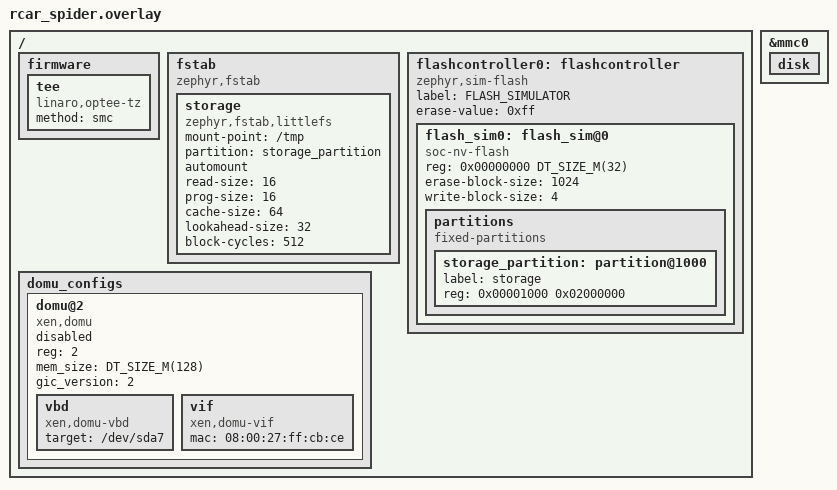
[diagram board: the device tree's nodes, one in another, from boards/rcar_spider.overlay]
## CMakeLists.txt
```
#
# Copyright (C) 2023 Renesas Electronics Corporation.
# Copyright (C) 2023 EPAM Systems, Inc.
#
# SPDX-License-Identifier: Apache-2.0
#

cmake_minimum_required(VERSION 3.20.0)

find_package(Zephyr REQUIRED HINTS $ENV{ZEPHYR_BASE})

include($ENV{ZEPHYR_BASE}/cmake/app/boilerplate.cmake NO_POLICY_SCOPE)

project(aoszephyrapp)

# ######################################################################################################################
# Config
# ######################################################################################################################

set(AOS_CORE_CONFIG aoscoreconfig.hpp)

# ######################################################################################################################
# Includes
# ######################################################################################################################

zephyr_include_directories(${CMAKE_CURRENT_BINARY_DIR} ${CMAKE_CURRENT_BINARY_DIR}/proto src)
zephyr_include_directories_ifdef(CONFIG_NATIVE_APPLICATION mocks/include)

# ######################################################################################################################
# Build in Aos Root CA
# ######################################################################################################################

if(CONFIG_AOS_ROOT_CA_PATH)
    target_sources(app PRIVATE src/rootca/rootca.S)
endif()

# ######################################################################################################################
# Generate OPTEE TA tables
# ######################################################################################################################

if(CONFIG_TA_DEPLOY_DIR)
    file(MAKE_DIRECTORY ${CMAKE_CURRENT_BINARY_DIR}/optee)

    set(GENERATED_DIRECTORY ${CMAKE_CURRENT_BINARY_DIR}/optee)

    execute_process(
        COMMAND ${PYTHON_EXECUTABLE} ${CMAKE_CURRENT_SOURCE_DIR}/scripts/gen_ta_src.py -s
                ${CMAKE_CURRENT_BINARY_DIR}/${CONFIG_TA_DEPLOY_DIR} -p -o ${GENERATED_DIRECTORY}/ta_table
    )

    include_directories(app PRIVATE ${CMAKE_CURRENT_BINARY_DIR}/${CONFIG_TA_DEPLOY_DIR})
    target_sources(app PRIVATE ${GENERATED_DIRECTORY}/ta_table.c ${GENERATED_DIRECTORY}/ta_table.S)
endif()

# ######################################################################################################################
# Definitions
# ######################################################################################################################

# Aos core configuration
add_definitions(-include ${AOS_CORE_CONFIG})

# ######################################################################################################################
# Compile options
# ######################################################################################################################

# Add stack usage warning
target_compile_options(app PRIVATE -Wstack-usage=2048)

# ######################################################################################################################
# Taget
# ######################################################################################################################

target_sources(
    app
    PRIVATE src/main.cpp
            src/app/app.cpp
            src/clocksync/clocksync.cpp
            src/communication/channelmanager.cpp
            src/communication/tlschannel.cpp
            src/communication/channel.cpp
            src/communication/channelmanager.cpp
            src/downloader/downloader.cpp
            src/iamclient/iamclient.cpp
            src/image/imagehandler.cpp
            src/logger/fsbackend.cpp
            src/logger/logger.cpp
            src/logprovider/fslogreader.cpp
            src/logprovider/logprovider.cpp
            src/monitoring/resourceusageprovider.cpp
            src/nodeinfoprovider/nodeinfoprovider.cpp
            src/ocispec/ocispec.cpp
            src/provisionmanager/provisionmanagercallback.cpp
            src/resourcemanager/resourcemanager.cpp
            src/runner/consolereader.cpp
            src/runner/runner.cpp
            src/smclient/openhandler.cpp
            src/smclient/smclient.cpp
            src/storage/storage.cpp
            src/utils/checksum.cpp
            src/utils/fsplatform.cpp
            src/utils/utils.cpp
)

# use pipe for native posix
target_sources_ifdef(CONFIG_NATIVE_APPLICATION app PRIVATE src/communication/socket.cpp)

# use xenvchan for xen
target_sources_ifndef(CONFIG_NATIVE_APPLICATION app PRIVATE src/communication/xenvchan.cpp)

# Enable vchannels and xrun mocks for native posix
target_sources_ifdef(
    CONFIG_NATIVE_APPLICATION
    app
    PRIVATE
    mocks/vch/vch.cpp
    mocks/xenlib/xenconsole.cpp
    mocks/xenlib/xendommgmt.cpp
    mocks/xrun/xrun.cpp
    mocks/xstat/xstat.cpp
)

# Include domain IPL and dtb for xen_dom0 snippet
target_sources_ifdef(CONFIG_XEN_DOM0 app PRIVATE src/domains/dom_runner.c src/domains/domain_bins.S)

# Include source files for DomD support

target_sources_ifdef(CONFIG_SOC_SERIES_RCAR_GEN4 app PRIVATE src/domains/domd/domd_cfg_spider.c)
target_sources_ifdef(CONFIG_BOARD_RCAR_SALVATOR_XS_M3 app PRIVATE src/domains/domd/domd_cfg_salvator_xs.c)
target_sources_ifdef(CONFIG_BOARD_RCAR_H3ULCB_CA57 app PRIVATE src/domains/domd/domd_cfg_h3ulcb.c)

# Include configuration source file for DomU
target_sources_ifdef(CONFIG_DOMU_ENABLE app PRIVATE src/domains/domu/domu_cfg.c)

# Include HW-specific source file
target_sources_ifndef(CONFIG_NATIVE_APPLICATION app PRIVATE src/bsp/reboot.c src/bsp/mount.c)
target_sources_ifdef(CONFIG_FILE_SYSTEM_LITTLEFS app PRIVATE src/bsp/mount_littlefs.c)
target_sources_ifdef(CONFIG_FAT_FILESYSTEM_ELM app PRIVATE src/bsp/mount_fatfs.c)

# ######################################################################################################################
# Versioning
# ######################################################################################################################

find_package(Git)

if(NOT GIT_FOUND)
    set(GIT_EXECUTABLE git)
endif()

set(CMAKE_MODULE_PATH ${PROJECT_SOURCE_DIR}/cmake)

add_custom_target(
    version
    COMMAND
        ${CMAKE_COMMAND} -D GIT_EXECUTABLE=${GIT_EXECUTABLE} -D INPUT_FILE=${CMAKE_SOURCE_DIR}/src/version.hpp.in -D
        OUTPUT_FILE=${CMAKE_CURRENT_BINARY_DIR}/version.hpp -D GIT_SOURCE_DIR=${CMAKE_SOURCE_DIR} -P
        ${CMAKE_MODULE_PATH}/GenerateVersion.cmake
)

add_dependencies(app version)

# ######################################################################################################################
#  Generate API
# ######################################################################################################################

find_package(CoreAPI)

set(CORE_API_CXX_FLAGS
    -I${CMAKE_CURRENT_SOURCE_DIR}/src
    -I${CMAKE_CURRENT_SOURCE_DIR}/../aos_core_lib_cpp/include
    -imacros
    ${AUTOCONF_H}
    -include
    ${AOS_CORE_CONFIG}
    -DARCH_STACK_PTR_ALIGN=16
)

core_api_generate(${CMAKE_CURRENT_SOURCE_DIR}/../aos_core_api ${CMAKE_CURRENT_SOURCE_DIR}/scripts)

# ######################################################################################################################
# mbedTLS
# ######################################################################################################################

# Enable AESNI for posix 32bit
if(${CONFIG_BOARD_NATIVE_POSIX})
    target_compile_options(mbedTLS INTERFACE -mpclmul -msse2 -maes)
endif()

# WA to have get time on zephyr
target_compile_definitions_ifndef(CONFIG_NATIVE_APPLICATION mbedTLS INTERFACE _POSIX_VERSION=200809L)

# Add Aos psa driver

set(mbedtls_source_dir "${APPLICATION_SOURCE_DIR}/../modules/crypto/mbedtls")
set(aoscore_source_dir "${APPLICATION_SOURCE_DIR}/../aos_core_lib_cpp")

set_source_files_properties(
    ${mbedtls_source_dir}/library/psa_crypto_driver_wrappers_no_static.c ${mbedtls_source_dir}/library/psa_crypto.c
    TARGET_DIRECTORY mbedTLS PROPERTIES HEADER_FILE_ONLY ON
)

target_include_directories(mbedTLSCrypto PRIVATE ${mbedtls_source_dir}/library)

target_sources(
    mbedTLSCrypto
    PRIVATE ${aoscore_source_dir}/src/common/crypto/mbedtls/drivers/psa_crypto_driver_wrappers_no_static.c
            ${aoscore_source_dir}/src/common/crypto/mbedtls/drivers/psa_crypto.c ${mbedtls_source_dir}/library/pk_ecc.c
)

target_sources(mbedTLSX509 PRIVATE ${mbedtls_source_dir}/library/x509write.c)

# ######################################################################################################################
# External libs
# ######################################################################################################################

include(ExternalProject)

zephyr_get_include_directories_for_lang_as_string(CXX includes)
zephyr_get_system_include_directories_for_lang_as_string(CXX system_includes)
zephyr_get_compile_definitions_for_lang_as_string(CXX definitions)
zephyr_get_compile_options_for_lang_as_string(CXX options)

set(external_project_cxx_flags "${includes} ${system_includes} -imacros ${AUTOCONF_H} ${definitions} ${options}")

# ######################################################################################################################
# aos_core_lib_cpp
# ######################################################################################################################

# add mbedTLS includes and defines for Aos core lib
set(mbedtls_includes "-I$<JOIN:$<TARGET_PROPERTY:mbedTLS,INTERFACE_INCLUDE_DIRECTORIES>, -I>")
set(mbedtls_definitions "-D$<JOIN:$<TARGET_PROPERTY:mbedTLS,INTERFACE_COMPILE_DEFINITIONS>, -D>")

set(aos_cxx_flags
    "${external_project_cxx_flags} -include ${AOS_CORE_CONFIG} ${mbedtls_includes} '${mbedtls_definitions}' \
    -Wno-pedantic -Wno-error"
)
set(aoscore_build_dir ${CMAKE_CURRENT_BINARY_DIR}/aoscore)

ExternalProject_Add(
    aoscore
    PREFIX ${aoscore_build_dir}
    CMAKE_ARGS -DCMAKE_INSTALL_PREFIX=${aoscore_build_dir}
               -DCMAKE_C_COMPILER=${CMAKE_C_COMPILER}
               -DCMAKE_CXX_COMPILER=${CMAKE_CXX_COMPILER}
               -DCMAKE_SYSTEM_NAME=${CMAKE_SYSTEM_NAME}
               -DCMAKE_SYSTEM_PROCESSOR=${CMAKE_SYSTEM_PROCESSOR}
               -DCMAKE_CXX_FLAGS=${aos_cxx_flags}
               -DWITH_MBEDTLS=OFF
    SOURCE_DIR ${aoscore_source_dir}
    BUILD_BYPRODUCTS ${aoscore_build_dir}/lib/libaossm.a ${aoscore_build_dir}/lib/libaosiam.a
                     ${aoscore_build_dir}/lib/libaoscommon.a ${aoscore_build_dir}/lib/libaoscrypto.a
    DEPENDS zephyr_interface
)

file(MAKE_DIRECTORY ${aoscore_build_dir}/include)

# aossm

add_library(aossm STATIC IMPORTED GLOBAL)

add_dependencies(aossm aoscore)

set_target_properties(aossm PROPERTIES IMPORTED_LOCATION ${aoscore_build_dir}/lib/libaossm.a)
set_target_properties(aossm PROPERTIES INTERFACE_INCLUDE_DIRECTORIES ${aoscore_build_dir}/include)

target_link_libraries(app PUBLIC aossm)

# aosiam

add_library(aosiam STATIC IMPORTED GLOBAL)

add_dependencies(aosiam aoscore)

set_target_properties(aosiam PROPERTIES IMPORTED_LOCATION ${aoscore_build_dir}/lib/libaosiam.a)
set_target_properties(aosiam PROPERTIES INTERFACE_INCLUDE_DIRECTORIES ${aoscore_build_dir}/include)

target_link_libraries(app PUBLIC aosiam)

# aoscommon

add_library(
    aoscommon STATIC ${aoscore_source_dir}/src/common/crypto/mbedtls/cryptoprovider.cpp
                     ${aoscore_source_dir}/src/common/crypto/mbedtls/driverwrapper.cpp
)

add_dependencies(aoscommon aoscore)

target_link_libraries(
    aoscommon PUBLIC ${aoscore_build_dir}/lib/libaoscommon.a ${aoscore_build_dir}/lib/libaoscrypto.a mbedTLSCrypto
)
target_include_directories(
    aoscommon
    PUBLIC ${aoscore_build_dir}/include
    PRIVATE ${CMAKE_CURRENT_SOURCE_DIR}/src
)

target_link_libraries(app PUBLIC aoscommon)

# ######################################################################################################################
# Prepare softhsm2 config
# ######################################################################################################################

if(CONFIG_NATIVE_APPLICATION)
    set(tokendir ${CONFIG_AOS_HSM_DIR})

    if(NOT IS_ABSOLUTE ${tokendir})
        set(tokendir ${CMAKE_CURRENT_BINARY_DIR}/${tokendir})
    endif()

    file(COPY misc/softhsm2.conf DESTINATION ${CMAKE_CURRENT_BINARY_DIR}/softhsm)
    file(APPEND ${CMAKE_CURRENT_BINARY_DIR}/softhsm/softhsm2.conf "directories.tokendir = ${tokendir}/\n")
endif()
```

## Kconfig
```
# Copyright (C) 2023 Renesas Electronics Corporation.
# Copyright (C) 2023 EPAM Systems, Inc.
#
# SPDX-License-Identifier: Apache-2.0

mainmenu "Aos zephyr application"

config AOS_ENABLE
	bool "Enable Aos"
	default y

config AOS_DOMD_ID
	int "DomD id"
	default 1

config AOS_CHAN_TX_PATH
	string "Path to TX channel"
	depends on !NATIVE_APPLICATION
	default "/local/domain/1/tmp/vchan/aos/tx"

config AOS_CHAN_RX_PATH
	string "Path to RX channel"
	depends on !NATIVE_APPLICATION
	default "/local/domain/1/tmp/vchan/aos/rx"

config AOS_REBOOT_XEN_STORE_PATH
	string "Path to user reboot request"
	default "/local/domain/1/data/user-reboot"

config AOS_DISK_MOUNT_POINT
	string "Disk mount point"
	default "/lfs"

config AOS_LOG_BACKEND_FS_DIR
	string "Path to the log directory"
	default "/lfs/aos/logs"

config AOS_LOG_BACKEND_FS_FILE_SIZE
	int "Log file size"
	default 16384

config AOS_LOG_BACKEND_FS_FILE_PREFIX
	string "Log file prefix"
	default "log_"

config AOS_LOG_BACKEND_FS_FILES_LIMIT
	int "Log file count"
	default 8

config AOS_STORAGE_DIR
	string "Path to the storage"
	default "/lfs/aos/storage"

config AOS_RUNTIME_DIR
	string "Aos runtime dir"
	default "/tmp/aos/runtime"

config AOS_DOWNLOAD_DIR
	string "Aos download dir"
	default "/lfs/aos/download"

config AOS_SERVICES_DIR
	string "Aos services dir"
	default "/lfs/aos/services"

config AOS_LAYERS_DIR
	string "Aos layers dir"
	default "/lfs/aos/layers"

config AOS_LAUNCHER_STATE_DIR
	string "Aos launcher state dir"
	default "/lfs/aos/launcher/states"

config AOS_LAUNCHER_STORAGE_DIR
	string "Aos launcher storage dir"
	default "/lfs/aos/launcher/storages"

config AOS_LAUNCHER_WORK_DIR
	string "Aos launcher work dir"
	default "/lfs/aos/launcher"

config AOS_NODE_CONFIG_FILE
	string "Node configuration file path"
	default "/lfs/aos/node_config.cfg"

config AOS_NODE_STATUS_FILE
	string "Path to provisioning state file."
	default "/lfs/aos/.nodestatus"

config AOS_NODE_ID_FILE
	string "Path to node id file."
	default "/lfs/aos/node-id"

config AOS_PKCS11_MODULE_PIN_FILE
	string "Path to PKCS11 module PIN file."
	default "/lfs/aos/.pkcs11pin"

config AOS_HSM_DIR
	string "Path HSM tokens dir."
	default "/lfs/tee"

config AOS_NODE_NAME
	string "Node name"
	default "zephyr"

config AOS_NODE_TYPE
	string "Node type"
	default "NODE_TYPE1"

config AOS_CLOCK_SYNC_SEND_PERIOD_SEC
	int "Send clock sync period in seconds"
	default 60

config AOS_CLOCK_SYNC_TIMEOUT_SEC
	int "Clock becomes unsynced if there is no clock sync update during this period."
	default 600

config AOS_CLOCK_SYNC_MAX_DIFF_MSEC
	int "Maximum allowed difference between source and current time."
	default 10000

config AOS_MAX_CPU_DMIPS
	int "Maximum CPU DMIPS"
	default 10000

config AOS_ROOT_CA_PATH
	string "Path to Aos Root CA certificate. Required to build in root CA into app image."
	default "prebuilt/rootca.pem"

config AOS_IAM_OPEN_PORT
	int "Aos IAM open port"
	default 1

config AOS_IAM_SECURE_PORT
	int "Aos IAM secure port"
	default 2

config AOS_SM_OPEN_PORT
	int "Aos SM open port"
	default 3

config AOS_SM_SECURE_PORT
	int "Aos SM secure port"
	default 4

config AOS_SOCKET_SERVER_ADDRESS
	string "Aos socket server address"
	depends on NATIVE_APPLICATION
	default "10.0.0.100"

config AOS_SOCKET_SERVER_PORT
	int "Aos socket server port"
	depends on NATIVE_APPLICATION
	default 30001

config AOS_PBHANDLER_THREAD_STACK_SIZE
	int "Aos PB handler stack size"
	default 32768

config AOS_LAUNCHER_THREAD_STACK_SIZE
	int "Aos launcher stack size"
	default 32768

config DOMD_ENABLE
	bool "Enable Domain-D creation"
	default y

config DOMD_UBOOT_PATH
	string "Location for Domain-D IPL binary"
	depends on DOMD_ENABLE
	default "prebuilt/ipl.bin"

config DOMD_DTB_PATH
	string "Location of Domain-D partial device-tree"
	depends on DOMD_ENABLE
	default "prebuilt/ipl.dtb"

config DOMU_ENABLE
	bool "Enable Domain-U creation"

config DOMU_BIN_PATH
	string "Location for Domain-U binary"
	depends on DOMU_ENABLE
	default "prebuilt/domu.bin"

config DOMU_DTB_PATH
	string "Location for Domain-U device-tree"
	depends on DOMU_ENABLE
	default "prebuilt/domu.dtb"

config TA_DEPLOY_DIR
	string "Location of optee TA's deploy dir"

module = AOS_CORE
module-str = Aos core
source "subsys/logging/Kconfig.template.log_config"

module = AOS_CORE_RUNTIME
module-str = Aos core runtime
source "subsys/logging/Kconfig.template.log_config"

source "Kconfig"
```

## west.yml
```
#
# Copyright (C) 2023 Renesas Electronics Corporation.
# Copyright (C) 2023 EPAM Systems, Inc.
#
# SPDX-License-Identifier: Apache-2.0
#

# West YAML manifest for Zephyr as Xen Dom0

manifest:
  self:
    path: aos_core_zephyr

  remotes:
    - name: xen-troops
      url-base: https://github.com/xen-troops

    - name: aosedge
      url-base: https://github.com/aosedge

    - name: zephyrproject-rtos
      url-base: https://github.com/zephyrproject-rtos

  projects:
    - name: zephyr
      remote: xen-troops
      revision: "zephyr/v3.6.0/xt-v3.0.0"
      west-commands: scripts/west-commands.yml

    - name: aos_core_lib_cpp
      remote: aosedge
      revision: "v1.2.2"

    - name: aos_core_api
      remote: aosedge
      revision: "v8.2.0"

    - name: zephyr-xenlib
      remote: xen-troops
      revision: "v3.1.0"

    - name: zephyr-optee-client
      remote: xen-troops
      revision: "v0.1.1"

    - name: zephyr-xrun
      remote: xen-troops
      revision: "v0.1.0"

    - name: littlefs
      remote: zephyrproject-rtos
      revision: "ed0531d59ee37f5fb2762bcf2fc8ba4efaf82656"
      path: modules/fs/littlefs
      groups:
        - fs

    - name: fatfs
      remote: zephyrproject-rtos
      revision: "427159bf95ea49b7680facffaa29ad506b42709b"
      path: modules/fs/fatfs
      groups:
        - fs

    - name: nanopb
      remote: zephyrproject-rtos
      revision: "65cbefb4695bc7af1cb733ced99618afb3586b20"
      path: modules/lib/nanopb

    - name: mbedtls
      remote: zephyrproject-rtos
      revision: "a78176c6ff0733ba08018cba4447bd3f20de7978"
      path: modules/crypto/mbedtls
      groups:
        - crypto
```

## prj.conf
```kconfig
#
# Copyright (c) 2023 EPAM Systems
#
# SPDX-License-Identifier: Apache-2.0
#

# ######################################################################################################################
# System params
# ######################################################################################################################

# Set mem parameters
CONFIG_HEAP_MEM_POOL_SIZE=2097152

# Enable userspace
CONFIG_USERSPACE=y

# Set stack size
CONFIG_MAIN_STACK_SIZE=32768
CONFIG_ISR_STACK_SIZE=8192

# Select lib
CONFIG_NEWLIB_LIBC=y
CONFIG_NEWLIB_LIBC_NANO=n

# Increase KOBJECT RODATA
CONFIG_KOBJECT_RODATA_AREA_EXTRA_BYTES=2048

# ######################################################################################################################
# Enable C++
# ######################################################################################################################

CONFIG_CPP=y
CONFIG_STD_CPP17=y

# ######################################################################################################################
# Logging, errors etc.
# ######################################################################################################################

# Enable logging

CONFIG_LOG_OUTPUT_FORMAT_CUSTOM_TIMESTAMP=y

CONFIG_LOG=y
CONFIG_LOG_CMDS=y
CONFIG_LOG_FUNC_NAME_PREFIX_ERR=n
CONFIG_LOG_FUNC_NAME_PREFIX_WRN=n
CONFIG_LOG_FUNC_NAME_PREFIX_INF=n
CONFIG_LOG_FUNC_NAME_PREFIX_DBG=n
CONFIG_LOG_DEFAULT_LEVEL=3
CONFIG_LOG_MODE_DEFERRED=y
CONFIG_LOG_BUFFER_SIZE=8192

# Set kernel default log level
CONFIG_KERNEL_LOG_LEVEL_INF=y

# Disable FS log to avoid errors duplication. We catch them by Aos errors.
CONFIG_FS_LOG_LEVEL_OFF=y

# Disable pthread cond log. It displays error on cond wait with timeout.
CONFIG_PTHREAD_COND_LOG_LEVEL_OFF=y

# Set Aos log level
CONFIG_AOS_CORE_LOG_LEVEL_DBG=y

# Set Aos runtime log level
CONFIG_AOS_CORE_RUNTIME_LOG_LEVEL_INF=y

# Enable assert for debugging purposes
# TODO: remove for release
CONFIG_ASSERT=y

# ######################################################################################################################
# POSIX configuration
# ######################################################################################################################

CONFIG_PTHREAD_IPC=y
CONFIG_POSIX_API=y
CONFIG_POSIX_FS=y
CONFIG_MAX_PTHREAD_COUNT=32
CONFIG_MAX_PTHREAD_MUTEX_COUNT=128
CONFIG_MAX_PTHREAD_COND_COUNT=32
CONFIG_MAX_THREAD_BYTES=5

# ######################################################################################################################
# 3rd parties modules
# ######################################################################################################################

# Enable mbedtls

CONFIG_MBEDTLS=y
CONFIG_MBEDTLS_BUILTIN=y
CONFIG_MBEDTLS_ENABLE_HEAP=y
CONFIG_MBEDTLS_HEAP_SIZE=262144
CONFIG_MBEDTLS_ZEPHYR_ENTROPY=y
CONFIG_MBEDTLS_USER_CONFIG_ENABLE=y
CONFIG_MBEDTLS_USER_CONFIG_FILE="aosmbedtlsconfig.h"

CONFIG_MBEDTLS_CIPHER_CCM_ENABLED=y
CONFIG_MBEDTLS_ECDH_C=y
CONFIG_MBEDTLS_ECDSA_C=y
CONFIG_MBEDTLS_ECP_C=y
CONFIG_MBEDTLS_ECP_DP_SECP256R1_ENABLED=y
CONFIG_MBEDTLS_ECP_DP_SECP384R1_ENABLED=y
CONFIG_MBEDTLS_KEY_EXCHANGE_ECDHE_ECDSA_ENABLED=y
CONFIG_MBEDTLS_KEY_EXCHANGE_RSA_ENABLED=y
CONFIG_MBEDTLS_PEM_CERTIFICATE_FORMAT=y
CONFIG_MBEDTLS_PK_WRITE_C=y
CONFIG_MBEDTLS_PSA_CRYPTO_C=y
CONFIG_MBEDTLS_SSL_MAX_CONTENT_LEN=16384
CONFIG_MBEDTLS_TLS_VERSION_1_2=y

# Enable JSON library

CONFIG_JSON_LIBRARY=y

# Enable nanopb library

CONFIG_NANOPB=y

# ######################################################################################################################
# System components
# ######################################################################################################################

# Enable shell support

CONFIG_SHELL=y
CONFIG_SHELL_BACKEND_SERIAL=y
CONFIG_SHELL_CMD_BUFF_SIZE=512
CONFIG_SHELL_STACK_SIZE=8192
CONFIG_SHELL_BACKEND_SERIAL_RX_RING_BUFFER_SIZE=512

# Enable file system

CONFIG_FILE_SYSTEM=y
CONFIG_FILE_SYSTEM_SHELL=y
CONFIG_FILE_SYSTEM_MKFS=y

# Enable cpu power management
CONFIG_PM_CPU_OPS=y

# Requires by mbedTLS for entropy. Need to be replaced with HW solution.
CONFIG_TEST_RANDOM_GENERATOR=y

# ######################################################################################################################
# Enable OP-TEE driver and client libraries
# ######################################################################################################################

CONFIG_TEE=y
CONFIG_OPTEE=y

CONFIG_OPTEE_CLIENT=y
CONFIG_OPTEE_LIBTEEC=y
CONFIG_OPTEE_LIBCKTEEC=y
CONFIG_OPTEE_TEE_SUPPLICANT=y
CONFIG_OPTEE_TEE_SUPPLICANT_AUTOINIT=n
CONFIG_OPTEE_STORAGE_ROOT="/lfs/tee"

# ######################################################################################################################
# Xen and its components
# ######################################################################################################################

# Enable xen

CONFIG_XEN_DOMAIN_MANAGEMENT=y
CONFIG_XEN_CONSOLE_SRV=y
CONFIG_XEN_STORE_SRV=y
CONFIG_XEN_LIBFDT=y
CONFIG_XEN_SHELL=y

# Enable xrun

CONFIG_XRUN=y
CONFIG_XRUN_SHELL_CMDS=y

# Enable xstat

CONFIG_XSTAT=y
CONFIG_XSTAT_SHELL_CMDS=y

# Enable vchan

CONFIG_XEN_VCH=y
CONFIG_VCH_PATH_MAXLEN=48
```

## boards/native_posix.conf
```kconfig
#
# Copyright (c) 2023 EPAM Systems
#
# SPDX-License-Identifier: Apache-2.0
#

# Enable heap auto configuration

CONFIG_SYS_HEAP_AUTO=y

# Disable Newlib

CONFIG_NEWLIB_LIBC=n
CONFIG_NEWLIB_LIBC_NANO=n

# Configure logs

CONFIG_LOG_DEFAULT_LEVEL=4
CONFIG_LOG_BACKEND_NATIVE_POSIX=y
CONFIG_SHELL_LOG_BACKEND=n
CONFIG_LOG_MODE_IMMEDIATE=y

# Enable debugging

CONFIG_NO_OPTIMIZATIONS=y
CONFIG_DEBUG_INFO=y
CONFIG_DEBUG=y

# Slow down to real time

CONFIG_NATIVE_POSIX_SLOWDOWN_TO_REAL_TIME=y

# Disable userspace

CONFIG_USERSPACE=n

# Disable errno strerror

CONFIG_MINIMAL_LIBC_STRING_ERROR_TABLE=n

# Disable posix config

CONFIG_PTHREAD_IPC=n
CONFIG_POSIX_API=n
CONFIG_POSIX_FS=n
CONFIG_MAX_PTHREAD_COUNT=0
CONFIG_MAX_PTHREAD_MUTEX_COUNT=0
CONFIG_MAX_THREAD_BYTES=0

# Disable cpu power management

CONFIG_PM_CPU_OPS=n

# Disable xen

CONFIG_XEN_DOMAIN_MANAGEMENT=n
CONFIG_XEN_CONSOLE_SRV=n
CONFIG_XEN_STORE_SRV=n
CONFIG_XEN_LIBFDT=n
CONFIG_XEN_STORE_SRV=n
CONFIG_XEN_SHELL=n

# Disable vchan

CONFIG_XEN_VCH=n

# Disable xstat

CONFIG_XSTAT=n
CONFIG_XSTAT_SHELL_CMDS=n

# Disable xrun

CONFIG_XRUN=n
CONFIG_XRUN_SHELL_CMDS=n

# Application config

CONFIG_AOS_DISK_MOUNT_POINT=".aos"
CONFIG_AOS_STORAGE_DIR=".aos/storage"
CONFIG_AOS_RUNTIME_DIR=".aos/runtime"
CONFIG_AOS_DOWNLOAD_DIR=".aos/download"
CONFIG_AOS_SERVICES_DIR=".aos/services"
CONFIG_AOS_LAUNCHER_STATE_DIR=".aos/launcher/states"
CONFIG_AOS_LAUNCHER_STORAGE_DIR=".aos/launcher/storages"
CONFIG_AOS_LAUNCHER_WORK_DIR=".aos/launcher"
CONFIG_AOS_LAYERS_DIR=".aos/layers"
CONFIG_AOS_NODE_CONFIG_FILE=".aos/node_config.cfg"
CONFIG_AOS_HSM_DIR=".aos/hsm"
CONFIG_AOS_NODE_STATUS_FILE=".aos/.nodestatus"
CONFIG_AOS_NODE_ID_FILE=".aos/node-id"
CONFIG_AOS_PKCS11_MODULE_PIN_FILE=".aos/.pkcs11pin"

# Disable OP-TEE driver and client libraries
# TEE is not supported by this platform
CONFIG_TEE=n
CONFIG_OPTEE=n

CONFIG_OPTEE_CLIENT=n
CONFIG_OPTEE_LIBTEEC=n
CONFIG_OPTEE_LIBCKTEEC=n
CONFIG_OPTEE_TEE_SUPPLICANT=n
```

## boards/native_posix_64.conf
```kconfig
#
# Copyright (c) 2023 EPAM Systems
#
# SPDX-License-Identifier: Apache-2.0
#

# Enable heap auto configuration

CONFIG_SYS_HEAP_AUTO=y

# Disable Newlib

CONFIG_NEWLIB_LIBC=n
CONFIG_NEWLIB_LIBC_NANO=n

# Configure logs

CONFIG_LOG_DEFAULT_LEVEL=4
CONFIG_LOG_BACKEND_NATIVE_POSIX=y
CONFIG_SHELL_LOG_BACKEND=n
CONFIG_LOG_MODE_IMMEDIATE=y

# Enable debugging

CONFIG_NO_OPTIMIZATIONS=y
CONFIG_DEBUG_INFO=y
CONFIG_DEBUG=y

# Slow down to real time

CONFIG_NATIVE_POSIX_SLOWDOWN_TO_REAL_TIME=y

# Disable userspace

CONFIG_USERSPACE=n

# Disable errno strerror

CONFIG_MINIMAL_LIBC_STRING_ERROR_TABLE=n

# Disable posix config

CONFIG_PTHREAD_IPC=n
CONFIG_POSIX_API=n
CONFIG_POSIX_FS=n
CONFIG_MAX_PTHREAD_COUNT=0
CONFIG_MAX_PTHREAD_MUTEX_COUNT=0
CONFIG_MAX_THREAD_BYTES=0

# Disable cpu power management

CONFIG_PM_CPU_OPS=n

# Disable xen

CONFIG_XEN_DOMAIN_MANAGEMENT=n
CONFIG_XEN_CONSOLE_SRV=n
CONFIG_XEN_STORE_SRV=n
CONFIG_XEN_LIBFDT=n
CONFIG_XEN_STORE_SRV=n
CONFIG_XEN_SHELL=n

# Disable vchan

CONFIG_XEN_VCH=n

# Disable xstat

CONFIG_XSTAT=n
CONFIG_XSTAT_SHELL_CMDS=n

# Disable xrun

CONFIG_XRUN=n
CONFIG_XRUN_SHELL_CMDS=n

# Application config

CONFIG_AOS_DISK_MOUNT_POINT=".aos"
CONFIG_AOS_STORAGE_DIR=".aos/storage"
CONFIG_AOS_RUNTIME_DIR=".aos/runtime"
CONFIG_AOS_DOWNLOAD_DIR=".aos/download"
CONFIG_AOS_SERVICES_DIR=".aos/services"
CONFIG_AOS_LAYERS_DIR=".aos/layers"
CONFIG_AOS_NODE_CONFIG_FILE=".aos/node_config.cfg"
CONFIG_AOS_HSM_DIR=".aos/hsm"
CONFIG_AOS_NODE_STATUS_FILE=".aos/.nodestatus"
CONFIG_AOS_NODE_ID_FILE=".aos/node-id"
CONFIG_AOS_PKCS11_MODULE_PIN_FILE=".aos/.pkcs11pin"

# Disable OP-TEE driver and client libraries
# TEE is not supported by this platform
CONFIG_TEE=n
CONFIG_OPTEE=n

CONFIG_OPTEE_CLIENT=n
CONFIG_OPTEE_LIBTEEC=n
CONFIG_OPTEE_LIBCKTEEC=n
CONFIG_OPTEE_TEE_SUPPLICANT=n
```

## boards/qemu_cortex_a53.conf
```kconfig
#
# Copyright (c) 2023 EPAM Systems
#
# SPDX-License-Identifier: Apache-2.0
#

# Set mem parameters

CONFIG_MAX_XLAT_TABLES=24
CONFIG_KERNEL_VM_SIZE=0x4000000
```

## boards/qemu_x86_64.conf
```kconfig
#
# Copyright (c) 2023 EPAM Systems
#
# SPDX-License-Identifier: Apache-2.0
#

CONFIG_KERNEL_VM_SIZE=0x4000000

# Enable heap auto configuration

CONFIG_SYS_HEAP_AUTO=y

# Disable littlefs

CONFIG_FILE_SYSTEM_LITTLEFS=n

# Disable cpu power management

CONFIG_PM_CPU_OPS=n

# Disable xen

CONFIG_XEN_DOMAIN_MANAGEMENT=n
CONFIG_XEN_INITIAL_DOMAIN=n
CONFIG_XEN_CONSOLE_SRV=n
CONFIG_XEN_STORE_SRV=n
CONFIG_XEN_LIBFDT=n
CONFIG_XEN_STORE_SRV=n
CONFIG_XEN_SHELL=n

# Disable xrun

CONFIG_XRUN=n
CONFIG_XRUN_SHELL_CMDS=n

# Disable vchan

CONFIG_XEN_VCH=n

# Application config

CONFIG_AOS_STORAGE_DIR=".aos/storage"
CONFIG_AOS_RUNTIME_DIR=".aos/runtime"
CONFIG_AOS_SERVICES_DIR=".aos/services"
CONFIG_AOS_UNIT_CONFIG_FILE=".aos/unit_config.cfg"
```

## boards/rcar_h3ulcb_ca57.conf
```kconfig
#
# Copyright (c) 2023 EPAM Systems
#
# SPDX-License-Identifier: Apache-2.0
#

# Kernel virtual memory size

CONFIG_KERNEL_VM_SIZE=0x4000000
CONFIG_PARTIAL_DEVICE_TREE_SIZE=90000

CONFIG_DISK_ACCESS=y
CONFIG_DISK_DRIVERS=y
CONFIG_DISK_DRIVER_MMC=y

CONFIG_RCAR_MMC_SCC_SUPPORT=n
CONFIG_SD_DATA_TIMEOUT=1000

CONFIG_XEN_DOM0=y

# Configure LittleFS

CONFIG_FILE_SYSTEM_LITTLEFS=y
CONFIG_FS_LITTLEFS_FC_HEAP_SIZE=8192
CONFIG_FS_LITTLEFS_BLK_DEV=y
CONFIG_FS_LITTLEFS_CACHE_SIZE=512
CONFIG_FS_LITTLEFS_LOOKAHEAD_SIZE=2048
CONFIG_FS_LITTLEFS_NUM_FILES=8

# Enable FLASH

CONFIG_FLASH=y
CONFIG_FLASH_SHELL=y
CONFIG_FLASH_SIMULATOR=y
CONFIG_FLASH_MAP=y
```

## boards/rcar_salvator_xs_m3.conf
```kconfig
#
# Copyright (c) 2023 EPAM Systems
#
# SPDX-License-Identifier: Apache-2.0
#

# Kernel virtual memory size

CONFIG_KERNEL_VM_SIZE=0x4000000
CONFIG_PARTIAL_DEVICE_TREE_SIZE=70000

CONFIG_DISK_ACCESS=y
CONFIG_DISK_DRIVERS=y
CONFIG_DISK_DRIVER_MMC=y

CONFIG_RCAR_MMC_SCC_SUPPORT=n
CONFIG_SD_DATA_TIMEOUT=1000

CONFIG_XEN_DOM0=y

# Configure LittleFS

CONFIG_FILE_SYSTEM_LITTLEFS=y
CONFIG_FS_LITTLEFS_FC_HEAP_SIZE=8192
CONFIG_FS_LITTLEFS_BLK_DEV=y
CONFIG_FS_LITTLEFS_CACHE_SIZE=512
CONFIG_FS_LITTLEFS_LOOKAHEAD_SIZE=2048
CONFIG_FS_LITTLEFS_NUM_FILES=8

# Enable FLASH

CONFIG_FLASH=y
CONFIG_FLASH_SHELL=y
CONFIG_FLASH_SIMULATOR=y
CONFIG_FLASH_MAP=y
```

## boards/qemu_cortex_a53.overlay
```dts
/*
 * Copyright (C) 2023 Renesas Electronics Corporation.
 * Copyright (C) 2023 EPAM Systems, Inc.
 *
 * SPDX-License-Identifier: Apache-2.0
 */

#include <mem.h>

/ {
	fstab {
		compatible = "zephyr,fstab";
		storage: storage {
			compatible = "zephyr,fstab,littlefs";
			mount-point = "/aos";
			partition = <&storage_partition>;
			automount;
			read-size = <16>;
			prog-size = <16>;
			cache-size = <64>;
			lookahead-size = <32>;
			block-cycles = <512>;
		};
	};

	flashcontroller0: flashcontroller {
		compatible = "zephyr,sim-flash";
		label = "FLASH_SIMULATOR";
		#address-cells = <1>;
		#size-cells = <1>;
		erase-value = <0xff>;
		flash_sim0: flash_sim@0 {
			compatible = "soc-nv-flash";
			reg = <0x00000000 DT_SIZE_M(16)>;
			erase-block-size = <1024>;
			write-block-size = <4>;
			partitions {
				compatible = "fixed-partitions";
				#address-cells = <1>;
				#size-cells = <1>;
			/*
			 * Storage partition will be used by FCB/LittleFS/NVS
			 * if enabled.
			 */
				storage_partition: partition@1000 {
					label = "storage";
					reg = <0x00001000 0x01000000>;
				};
			};
		};
	};
};

&sram0 {
	reg = < 0x0 0x58000000 0x0 0x2000000 >;
};
```

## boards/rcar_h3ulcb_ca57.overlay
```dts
/*
 * Copyright (C) 2023 Renesas Electronics Corporation.
 * Copyright (C) 2023 EPAM Systems, Inc.
 *
 * SPDX-License-Identifier: Apache-2.0
 */

#include <mem.h>

/delete-node/ &sd0;
/delete-node/ &gpio5;
/delete-node/ &ram;

&emmc2 {
	disk {
		status = "okay";
	};
	status = "okay";
};

/ {
	/*
	 * This node may differs on different setups, please check
	 * following line in Xen boot log to set it right:
	 * (XEN) Grant table range: 0x00000088080000-0x000000880c0000
	 * Also, add extended region 2:
	 * (XEN) [    0.928173] d0: extended region 2: 0x40000000->0x47e00000
	 *
	 * Xen passes actual values for setup in domain device tree, but Zephyr
	 * is not capable to parse and handle it in runtime.
	 */
	hypervisor: hypervisor@88080000 {
		compatible = "xen,xen";
		reg = <0x0 0x88080000 0x0 0x40000 0x0 0x40000000 0x0 0x7e00000>;
		interrupts = <GIC_PPI 0x0 IRQ_TYPE_EDGE IRQ_DEFAULT_PRIORITY>;
		interrupt-parent = <&gic>;
		status = "okay";
	};

	/*
	 * This node may differs on different setups, because Xen picks
	 * region for Domain-0 for every specific configuration. You can
	 * start Xen for your platform and check following log:
	 * (XEN) Allocating 1:1 mappings for dom0:
	 * (XEN) BANK[0] 0x00000070000000-0x00000080000000 (256MB)
	 *
	 * Xen passes actual values for setup in domain device tree, but Zephyr
	 * is not capable to parse and handle it in runtime.
	 */
	ram: memory@70000000 {
		device_type = "mmio-sram";
		reg = <0x00 0x70000000 0x00 DT_SIZE_M(256)>;
	};

	firmware {
		tee {
		compatible = "linaro,optee-tz";
		method = "smc";
		status = "okay";
		};
	};

	fstab {
		compatible = "zephyr,fstab";
		storage: storage {
			compatible = "zephyr,fstab,littlefs";
			mount-point = "/tmp";
			partition = <&storage_partition>;
			automount;
			read-size = <16>;
			prog-size = <16>;
			cache-size = <64>;
			lookahead-size = <32>;
			block-cycles = <512>;
		};
	};

	flashcontroller0: flashcontroller {
		compatible = "zephyr,sim-flash";
		label = "FLASH_SIMULATOR";
		#address-cells = <1>;
		#size-cells = <1>;
		erase-value = <0xff>;
		flash_sim0: flash_sim@0 {
			compatible = "soc-nv-flash";
			reg = <0x00000000 DT_SIZE_M(32)>;
			erase-block-size = <1024>;
			write-block-size = <4>;
			partitions {
				compatible = "fixed-partitions";
				#address-cells = <1>;
				#size-cells = <1>;
				/*
				* Storage partition will be used by FCB/LittleFS/NVS
				* if enabled.
				*/
				storage_partition: partition@1000 {
					label = "storage";
					reg = <0x00001000 0x02000000>;
				};
			};
		};
	};
};
```

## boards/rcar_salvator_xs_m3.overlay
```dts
/*
 * Copyright (C) 2023 Renesas Electronics Corporation.
 * Copyright (C) 2023 EPAM Systems, Inc.
 *
 * SPDX-License-Identifier: Apache-2.0
 */

#include <mem.h>

/delete-node/ &ram;

&emmc2 {
	disk {
		status = "okay";
	};
	status = "okay";
};

/ {
	/*
	 * This node may differs on different setups, please check
	 * following line in Xen boot log to set it right:
	 * (XEN) Grant table range: 0x00000088080000-0x000000880c0000
	 * Also, add extended region 2:
	 * (XEN) [    0.928173] d0: extended region 2: 0x40000000->0x47e00000
	 *
	 * Xen passes actual values for setup in domain device tree, but Zephyr
	 * is not capable to parse and handle it in runtime.
	 */
	hypervisor: hypervisor@88080000 {
		compatible = "xen,xen";
		reg = <0x0 0x88080000 0x0 0x40000 0x0 0x40000000 0x0 0x7e00000>;
		interrupts = <GIC_PPI 0x0 IRQ_TYPE_EDGE IRQ_DEFAULT_PRIORITY>;
		interrupt-parent = <&gic>;
		status = "okay";
	};

	/*
	 * This node may differs on different setups, because Xen picks
	 * region for Domain-0 for every specific configuration. You can
	 * start Xen for your platform and check following log:
	 * (XEN) Allocating 1:1 mappings for dom0:
	 * (XEN) BANK[0] 0x00000070000000-0x00000080000000 (256MB)
	 *
	 * Xen passes actual values for setup in domain device tree, but Zephyr
	 * is not capable to parse and handle it in runtime.
	 */
	ram: memory@70000000 {
		device_type = "mmio-sram";
		reg = <0x00 0x70000000 0x00 DT_SIZE_M(256)>;
	};

	firmware {
		tee {
		compatible = "linaro,optee-tz";
		method = "smc";
		status = "okay";
		};
	};

	fstab {
		compatible = "zephyr,fstab";
		storage: storage {
			compatible = "zephyr,fstab,littlefs";
			mount-point = "/tmp";
			partition = <&storage_partition>;
			automount;
			read-size = <16>;
			prog-size = <16>;
			cache-size = <64>;
			lookahead-size = <32>;
			block-cycles = <512>;
		};
	};

	flashcontroller0: flashcontroller {
		compatible = "zephyr,sim-flash";
		label = "FLASH_SIMULATOR";
		#address-cells = <1>;
		#size-cells = <1>;
		erase-value = <0xff>;
		flash_sim0: flash_sim@0 {
			compatible = "soc-nv-flash";
			reg = <0x00000000 DT_SIZE_M(32)>;
			erase-block-size = <1024>;
			write-block-size = <4>;
			partitions {
				compatible = "fixed-partitions";
				#address-cells = <1>;
				#size-cells = <1>;
				/*
				* Storage partition will be used by FCB/LittleFS/NVS
				* if enabled.
				*/
				storage_partition: partition@1000 {
					label = "storage";
					reg = <0x00001000 0x02000000>;
				};
			};
		};
	};
};
```

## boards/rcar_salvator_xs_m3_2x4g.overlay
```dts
#include <mem.h>

/ {
	/delete-node/memory@60000000;
	ram: memory@70000000 {
		device_type = "mmio-sram";
		reg = <0x00 0x70000000 0x00 DT_SIZE_M(256)>;
	};
  	fstab {
		compatible = "zephyr,fstab";
		storage: storage {
			compatible = "zephyr,fstab,littlefs";
			mount-point = "/aos";
			partition = <&storage_partition>;
			automount;
			read-size = <16>;
			prog-size = <16>;
			cache-size = <64>;
			lookahead-size = <32>;
			block-cycles = <512>;
		};
	};
	flashcontroller0: flashcontroller {
		compatible = "zephyr,sim-flash";
		label = "FLASH_SIMULATOR";
		#address-cells = <1>;
		#size-cells = <1>;
		erase-value = <0xff>;
		flash_sim0: flash_sim@0 {
			compatible = "soc-nv-flash";
			reg = <0x00000000 DT_SIZE_M(32)>;
			erase-block-size = <1024>;
			write-block-size = <4>;
			partitions {
				compatible = "fixed-partitions";
				#address-cells = <1>;
				#size-cells = <1>;
			/*
			 * Storage partition will be used by FCB/LittleFS/NVS
			 * if enabled.
			 */
				storage_partition: partition@1000 {
					label = "storage";
					reg = <0x00001000 0x02000000>;
				};
			};
		};
	};
};
```

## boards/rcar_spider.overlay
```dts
/*
 * Copyright (C) 2023 Renesas Electronics Corporation.
 * Copyright (C) 2023 EPAM Systems, Inc.
 *
 * SPDX-License-Identifier: Apache-2.0
 */

#include <mem.h>

&mmc0 {
	disk {
		status = "okay";
	};
	status = "okay";
};

/ {
	firmware {
		tee {
		compatible = "linaro,optee-tz";
		method = "smc";
		status = "okay";
		};
	};

	fstab {
		compatible = "zephyr,fstab";
		storage: storage {
			compatible = "zephyr,fstab,littlefs";
			mount-point = "/tmp";
			partition = <&storage_partition>;
			automount;
			read-size = <16>;
			prog-size = <16>;
			cache-size = <64>;
			lookahead-size = <32>;
			block-cycles = <512>;
		};
	};

	flashcontroller0: flashcontroller {
		compatible = "zephyr,sim-flash";
		label = "FLASH_SIMULATOR";
		#address-cells = <1>;
		#size-cells = <1>;
		erase-value = <0xff>;
		flash_sim0: flash_sim@0 {
			compatible = "soc-nv-flash";
			reg = <0x00000000 DT_SIZE_M(32)>;
			erase-block-size = <1024>;
			write-block-size = <4>;
			partitions {
				compatible = "fixed-partitions";
				#address-cells = <1>;
				#size-cells = <1>;
				/*
				* Storage partition will be used by FCB/LittleFS/NVS
				* if enabled.
				*/
				storage_partition: partition@1000 {
					label = "storage";
					reg = <0x00001000 0x02000000>;
				};
			};
		};
	};

	domu_configs {
		#address-cells = <1>;
		#size-cells = <0>;

		domu@2 {
			/*
			 * Most of the properties of this one and children nodes are default and don't appear
			 * in the resulting dts.
			 *
			 * Refer to 'xen,domu.yaml', 'xen,domu-vbd.yaml' and 'xen,domu-vif.yaml' for details.
			 */
			compatible = "xen,domu";
			reg = <2>;

			mem_size = <DT_SIZE_M(128)>;
			gic_version = <2>;

			vbd {
				compatible = "xen,domu-vbd";
				target = "/dev/sda7";
			};

			vif {
				compatible = "xen,domu-vif";
				mac = "08:00:27:ff:cb:ce";
			};

			status = "disabled";
		};
	};
};
```

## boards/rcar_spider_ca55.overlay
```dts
/*
 * Copyright (C) 2023 Renesas Electronics Corporation.
 * Copyright (C) 2023 EPAM Systems, Inc.
 *
 * SPDX-License-Identifier: Apache-2.0
 */

#include <mem.h>

/delete-node/ &ram;

&mmc0 {
	disk {
		status = "okay";
	};
	status = "okay";
};

/ {
	/*
	 * This node may differs on different setups, please check
	 * following line in Xen boot log to set it right:
	 * (XEN) Grant table range: 0x00000078080000-0x000000780c0000
	 * Also, add extended region 1:
	 * (XEN) Extended region 1: 0x40000000->0x47e00000
	 *
	 * Xen passes actual values for setup in domain device tree, but Zephyr
	 * is not capable to parse and handle it in runtime.
	 */
	hypervisor: hypervisor@78080000 {
		compatible = "xen,xen";
		reg = <0x0 0x78080000 0x0 0x40000 0x0 0x40000000 0x0 0x7e00000>;
		interrupts = <GIC_PPI 0x0 IRQ_TYPE_EDGE IRQ_DEFAULT_PRIORITY>;
		interrupt-parent = <&gic>;
		status = "okay";
	};

	/*
	 * This node may differs on different setups, because Xen picks
	 * region for Domain-0 for every specific configuration. You can
	 * start Xen for your platform and check following log:
	 * (XEN) Allocating 1:1 mappings for dom0:
	 * (XEN) BANK[0] 0x00000080000000-0x00000090000000 (256MB)
	 *
	 * Xen passes actual values for setup in domain device tree, but Zephyr
	 * is not capable to parse and handle it in runtime.
	 */
	ram: memory@80000000 {
		device_type = "mmio-sram";
		reg = <0x00 0x80000000 0x00 DT_SIZE_M(256)>;
	};

	firmware {
		tee {
		compatible = "linaro,optee-tz";
		method = "smc";
		status = "okay";
		};
	};

	fstab {
		compatible = "zephyr,fstab";
		storage: storage {
			compatible = "zephyr,fstab,littlefs";
			mount-point = "/tmp";
			partition = <&storage_partition>;
			automount;
			read-size = <16>;
			prog-size = <16>;
			cache-size = <64>;
			lookahead-size = <32>;
			block-cycles = <512>;
		};
	};

	flashcontroller0: flashcontroller {
		compatible = "zephyr,sim-flash";
		label = "FLASH_SIMULATOR";
		#address-cells = <1>;
		#size-cells = <1>;
		erase-value = <0xff>;
		flash_sim0: flash_sim@0 {
			compatible = "soc-nv-flash";
			reg = <0x00000000 DT_SIZE_M(32)>;
			erase-block-size = <1024>;
			write-block-size = <4>;
			partitions {
				compatible = "fixed-partitions";
				#address-cells = <1>;
				#size-cells = <1>;
				/*
				* Storage partition will be used by FCB/LittleFS/NVS
				* if enabled.
				*/
				storage_partition: partition@1000 {
					label = "storage";
					reg = <0x00001000 0x02000000>;
				};
			};
		};
	};
};
```

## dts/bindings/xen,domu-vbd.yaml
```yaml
# Copyright (c) 2024 EPAM Systems
# SPDX-License-Identifier: Apache-2.0

description: Xen DomU configuration for virtual block device
compatible: "xen,domu-vbd"

include: base.yaml

properties:
  backend_domain_id:
    type: int
    default: 1
    description: |
      Designates a backend domain ID for the device.
      Specifies the backend domain ID which this device should attach to.

  target:
    type: string
    required: true
    description: |
      Block device or image file path.  When this is used as a path, /dev will be prepended
      if the path doesn't start with a '/'.

      Inside xenstore it is dirrectly written to 'params':
        a free formatted string providing sufficient information for the hotplug script to attach
        the device and provide a suitable handler (ie: a block device) for blkback to use.

  script:
    type: string
    default: "/etc/xen/scripts/block"
    description: |
      Specifies that <target> is not a normal host path, but rather information to be interpreted
      by the executable program <script>, (looked for in /etc/xen/scripts, if it doesn't contain
      a slash).

      These scripts are normally called "block-<script>".

  backendtype:
    type: string
    default: "phy"
    description: |
      Specifies the backend implementation to use. Supported values: phy, tap, qdisk.

      This does not affect the guest's view of the device.  It controls which software
      implementation of the Xen backend driver us used.

      Not all backend drivers support all combinations of other options. For example, "phy" does not
      support formats other than "raw". Normally this option should not be specified, in which case
      libxl will automatically determine the most suitable backend

  vdev:
    type: string
    default: "xvda"
    description: |
      Virtual device as seen by the guest (also referred to as guest drive designation in some
      specifications).

  access:
    type: string
    default: "rw"
    description: |
      Specified access control information. Whether or not the block device is provided to the
      guest in read-only or read-write mode depends on this attribute.

      Supported values:
        ro, r   (specifies read-only)
        rw, w   (specifies read/write)
```

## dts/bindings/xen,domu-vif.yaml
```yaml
# Copyright (c) 2024 EPAM Systems
# SPDX-License-Identifier: Apache-2.0

description: Xen DomU configuration for virtual network intreface
compatible: "xen,domu-vif"

include: base.yaml

properties:
  backend_domain_id:
    type: int
    default: 1
    description: |
      Designates a backend domain ID for the device.
      Specifies the backend domain ID which this device should attach to.

  script:
    type: string
    default: "/etc/xen/scripts/vif-bridge"
    description: |
      Specifies the hotplug script to run to configure this device (e.g. to add it to
      the relevant bridge).

  mac:
    type: string
    required: true # TODO: Remove when MAC generation is introduced in xen-dom-mgmt
    description: |
      If specified then this option specifies the MAC address inside the guest of this VIF device.
      The value is a 48-bit number represented as six groups of two hexadecimal digits, separated
      by colons.

      The default if this property is not specified is to be automatically generate a MAC address.

  bridge:
    type: string
    default: "xenbr0"
    description: |
      Specifies the name of the network bridge which this VIF should be added to. The bridge must
      be configured using your distribution's network configuration tools.

  vif_type:
    type: string
    default: "vif"
    description: |
      This keyword is valid for HVM guests only.
      Specifies the type of device to valid values are:

        "ioemu" -- this device will be provided as an emulate device to the guest and
                   also as a paravirtualised device which the guest may choose to use
                   instead if it has suitable drivers available.

        "vif"   -- this device will be provided as a paravirtualised device only.

  ip:
    type: string
    description: |
      Specifies the IP address for the device, the default is not to specify an IP address.

      What, if any, effect this has depends on the hotplug script which is configured. A typically
      behaviour (exhibited by the example hotplug scripts) if set might be to configure firewall
      rules to allow only the specified IP address to be used by the guest (blocking all others).
```

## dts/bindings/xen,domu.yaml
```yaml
# Copyright (c) 2024 EPAM Systems
# SPDX-License-Identifier: Apache-2.0

description: Xen DomU configuration
compatible: "xen,domu"

include: base.yaml

properties:
  mem_size:
    type: int
    default: 0x8000000 # by default 128M
    description: Size of the RAM given to domain

  max_evtchns:
    type: int
    default: 10

  max_vcpus:
    type: int
    default: 1

  gnt_frames:
    type: int
    default: 32

  max_maptrack_frames:
    type: int
    default: 1

  gic_version:
    type: int
    enum:
      - 0 # GIC Native
      - 1 # GICv2
      - 2 # GICv3
    default: 1

  cmdline:
    type: string
    default: "root=/dev/xvda rw rootwait console=hvc0 pci=pcie_bus_perf"
```

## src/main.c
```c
/*
 * Copyright (C) 2023 Renesas Electronics Corporation.
 * Copyright (C) 2023 EPAM Systems, Inc.
 *
 * SPDX-License-Identifier: Apache-2.0
 */

#include <stdio.h>

void main(void)
{
	printf("AOS Core zephyr app\n");
}
```

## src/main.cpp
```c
/*
 * Copyright (C) 2023 Renesas Electronics Corporation.
 * Copyright (C) 2023 EPAM Systems, Inc.
 *
 * SPDX-License-Identifier: Apache-2.0
 */

#include <zephyr/sys/__assert.h>
#include <zephyr/sys/printk.h>

#include <aos/common/tools/string.hpp>
#include <aos/common/version.hpp>

#include "app/app.hpp"
#include "logger/fsbackend.hpp"
#include "logger/logger.hpp"
#include "utils/utils.hpp"

// cppcheck-suppress missingInclude
#include "version.hpp"

#if !defined(CONFIG_NATIVE_APPLICATION)
#include <tee_supplicant.h>

#include "bsp/mount.h"
#include "bsp/reboot.h"
#include "domains/dom_runner.h"
#endif

using namespace aos::zephyr;

void RunAosApp()
{
    auto& app = aos::zephyr::app::App::Get();

    auto err = app.Init();
    __ASSERT(err.IsNone(), "Error initializing application: %s", utils::ErrorToCStr(err));

    err = app.Start();
    __ASSERT(err.IsNone(), "Error starting application: %s", utils::ErrorToCStr(err));
}

void SetAtExitHandler()
{
    atexit([]() {

#if defined(CONFIG_AOS_ENABLE)
        if (auto err = aos::zephyr::app::App::Get().Stop(); !err.IsNone()) {
            printk("Error stopping application: %s\n", utils::ErrorToCStr(err));

            _exit(1);
        }
#endif

        printk("Application stopped\n");

        _exit(0);
    });
}

int main(void)
{
    logger::backend::FSBackend::SetCustomTimestamp();

    printk("*** Aos zephyr application: %s ***\n", AOS_ZEPHYR_APP_VERSION);
    printk("*** Aos core library: %s ***\n", AOS_CORE_VERSION);
    printk("*** Aos core size: %lu ***\n", sizeof(app::App));

#if !defined(CONFIG_NATIVE_APPLICATION)
    auto ret = mount_fs();
    __ASSERT(ret == 0, "Error mounting FS: %s [%d]", strerror(ret), ret);

    ret = TEE_SupplicantInit();
    __ASSERT(ret == 0, "Error initializing TEE supplicant: %s [%d]", strerror(ret), ret);

    reboot_watcher_init();

    ret = create_domains();
    __ASSERT(ret == 0, "Error creating domains: %s [%d]", strerror(ret), ret);
#endif

    auto err = logger::Logger::Init();
    __ASSERT(err.IsNone(), "Error initializing logger: %s", utils::ErrorToCStr(err));

    err = logger::backend::FSBackend::Get().Init();
    __ASSERT(err.IsNone(), "Error initializing fs backend logger: %s", utils::ErrorToCStr(err));

#if defined(CONFIG_AOS_ENABLE)
    RunAosApp();
#endif

    SetAtExitHandler();

    return 0;
}
```

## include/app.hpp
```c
/*
 * Copyright (C) 2023 Renesas Electronics Corporation.
 * Copyright (C) 2023 EPAM Systems, Inc.
 *
 * SPDX-License-Identifier: Apache-2.0
 */

#include <aos/common/error.hpp>

/**
 * Aos zephyr application.
 */
class App {
public:
    /**
     * Initializes application.
     *
     * @return aos::Error
     */
    aos::Error Init();

    /**
     * Returns Aos application instance.
     * @return App&
     */
    static App& Get()
    {
        static App sApp;

        return sApp;
    };

private:
    App() {};
    App(App const&) = delete;
};
```

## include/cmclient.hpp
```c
/*
 * Copyright (C) 2023 Renesas Electronics Corporation.
 * Copyright (C) 2023 EPAM Systems, Inc.
 *
 * SPDX-License-Identifier: Apache-2.0
 */

#ifndef CMCLIENT_HPP_
#define CMCLIENT_HPP_

#include <aos/common/error.hpp>

class CMClient {
public:
    aos::Error Init();
};

#endif
```
